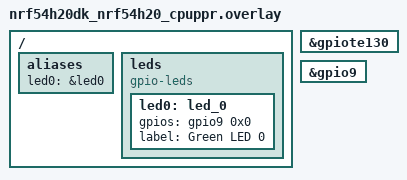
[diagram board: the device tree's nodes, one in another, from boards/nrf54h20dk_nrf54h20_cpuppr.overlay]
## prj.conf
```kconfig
CONFIG_ZTEST=y
CONFIG_GPIO=y
CONFIG_GPIO_GET_DIRECTION=y
```

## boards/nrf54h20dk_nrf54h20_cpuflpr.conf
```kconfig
# SPDX-License-Identifier: Apache-2.0

# FLPR does not support GPIO interrupts. Disabling interrupt support removes
# the driver's dependency on the (disabled-by-default) GPIOTE130 peripheral,
CONFIG_GPIO_NRFX_INTERRUPT=n
```

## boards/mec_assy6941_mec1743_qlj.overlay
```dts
/*
 * Copyright 2025 Microchip Technology Inc.
 *
 * SPDX-License-Identifier: Apache-2.0
 */

#include <dt-bindings/gpio/gpio.h>

/ {
	aliases {
		led0 = &led_G3;
	};

	gpio-led {
		compatible = "gpio-leds";

		led_G3: led_G3 {
			gpios = <&gpio_140_176 15 GPIO_ACTIVE_HIGH>;
		};
	};
};
```

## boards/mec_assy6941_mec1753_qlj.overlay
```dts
/*
 * Copyright 2025 Microchip Technology Inc.
 *
 * SPDX-License-Identifier: Apache-2.0
 */

#include <dt-bindings/gpio/gpio.h>

/ {
	aliases {
		led0 = &led_G3;
	};

	gpio-led {
		compatible = "gpio-leds";
		led_G3: led_G3 {
			gpios = <&gpio_140_176 15 GPIO_ACTIVE_HIGH>;
		};
	};
};
```

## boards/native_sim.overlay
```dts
&gpio0 {
	ngpios = <2>;
};
```

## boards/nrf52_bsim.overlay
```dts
/*
 * Copyright (c) 2023 Nordic Semiconductor ASA
 *
 * SPDX-License-Identifier: Apache-2.0
 */

/ {
	aliases {
		led0 = &led0;
	};

	leds {
		compatible = "gpio-leds";

		led0: led_0 {
			gpios = <&gpio0 0 GPIO_ACTIVE_HIGH>;
		};
	};
};
```

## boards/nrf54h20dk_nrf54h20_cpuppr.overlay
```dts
/* SPDX-License-Identifier: Apache-2.0 */

/ {
	aliases {
		led0 = &led0;
	};

	leds {
		compatible = "gpio-leds";
		led0: led_0 {
			gpios = < &gpio9 0x0 0x0 >;
			label = "Green LED 0";
		};
	};
};

&gpiote130 {
	status = "okay";
};

&gpio9 {
	status = "okay";
};
```

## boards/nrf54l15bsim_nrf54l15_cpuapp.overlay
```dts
/*
 * Copyright (c) 2024 Nordic Semiconductor ASA
 *
 * SPDX-License-Identifier: Apache-2.0
 */

#include "nrf52_bsim.overlay"
```

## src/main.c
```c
/*
 * Copyright (c) 2022 Meta
 *
 * SPDX-License-Identifier: Apache-2.0
 */

#include <zephyr/kernel.h>
#include <zephyr/drivers/gpio.h>
#include <zephyr/ztest.h>

#define TEST_NODE            DT_GPIO_CTLR(DT_ALIAS(led0), gpios)
#define TEST_PIN             DT_GPIO_PIN(DT_ALIAS(led0), gpios)
#define TEST_PIN_DTS_FLAGS   DT_GPIO_FLAGS(DT_ALIAS(led0), gpios)

struct gpio_get_direction_fixture {
	const struct device *port;
	gpio_pin_t pin;
	gpio_flags_t flags;
};

static void *gpio_get_direction_setup(void)
{
	static struct gpio_get_direction_fixture fixture;

	fixture.pin = TEST_PIN;
	fixture.port = DEVICE_DT_GET(TEST_NODE);

	return &fixture;
}

static void gpio_get_direction_before(void *arg)
{
	struct gpio_get_direction_fixture *fixture = (struct gpio_get_direction_fixture *)arg;

	zassert_true(device_is_ready(fixture->port), "GPIO device is not ready");
}

static void common(struct gpio_get_direction_fixture *fixture)
{
	int rv;

	rv = gpio_pin_configure(fixture->port, fixture->pin, fixture->flags);
	if (rv == -ENOTSUP) {
		/* some drivers / hw might not support e.g. input-output or disconnect */
		ztest_test_skip();
	}

	zassert_ok(rv, "gpio_pin_configure() failed: %d", rv);
}

ZTEST_F(gpio_get_direction, test_disconnect)
{
	int rv;

	fixture->flags = GPIO_DISCONNECTED;
	common(fixture);

	rv = gpio_pin_is_input(fixture->port, fixture->pin);
	if (rv == -ENOSYS) {
		/* gpio_pin_direction() is not supported in the driver */
		ztest_test_skip();
	}

	zassert_equal(false, rv, "gpio_pin_is_input() failed: %d", rv);

	rv = gpio_pin_is_output(fixture->port, fixture->pin);
	zassert_equal(false, rv, "gpio_pin_is_output() failed: %d", rv);
}

ZTEST_F(gpio_get_direction, test_input)
{
	int rv;
	fixture->flags = GPIO_INPUT;

	common(fixture);

	rv = gpio_pin_is_input(fixture->port, fixture->pin);
	if (rv == -ENOSYS) {
		/* gpio_pin_direction() is not supported in the driver */
		ztest_test_skip();
	}

	zassert_equal(true, rv, "gpio_pin_is_input() failed: %d", rv);

	rv = gpio_pin_is_output(fixture->port, fixture->pin);
	zassert_equal(false, rv, "gpio_pin_is_output() failed: %d", rv);
}

ZTEST_F(gpio_get_direction, test_output)
{
	int rv;
	fixture->flags = GPIO_OUTPUT | GPIO_OUTPUT_INIT_LOW;

	common(fixture);

	rv = gpio_pin_is_input(fixture->port, fixture->pin);
	if (rv == -ENOSYS) {
		/* gpio_pin_direction() is not supported in the driver */
		ztest_test_skip();
	}

	zassert_equal(false, rv, "gpio_pin_is_input() failed: %d", rv);

	rv = gpio_pin_is_output(fixture->port, fixture->pin);
	zassert_equal(true, rv, "gpio_pin_is_output() failed: %d", rv);
}

ZTEST_F(gpio_get_direction, test_input_output)
{
	int rv;
	fixture->flags = GPIO_INPUT | GPIO_OUTPUT | GPIO_OUTPUT_INIT_LOW;

	common(fixture);

	rv = gpio_pin_is_input(fixture->port, fixture->pin);
	if (rv == -ENOSYS) {
		/* some drivers / gpio hw do not support input-output mode */
		ztest_test_skip();
	}

	zassert_equal(true, rv, "gpio_pin_is_input() failed: %d", rv);

	rv = gpio_pin_is_output(fixture->port, fixture->pin);
	zassert_equal(true, rv, "gpio_pin_is_output() failed: %d", rv);
}

ZTEST_SUITE(gpio_get_direction, NULL, gpio_get_direction_setup, gpio_get_direction_before, NULL,
	    NULL);
```

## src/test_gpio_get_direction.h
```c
/*
 * Copyright (c) 2022 Meta
 *
 * SPDX-License-Identifier: Apache-2.0
 */

#ifndef TEST_GPIO_GET_DIRECTION_H_
#define TEST_GPIO_GET_DIRECTION_H_

#include <zephyr/zephyr.h>
#include <zephyr/drivers/gpio.h>
#include <ztest.h>

#if DT_NODE_HAS_PROP(DT_ALIAS(led0), gpios)
#define TEST_DEV             DT_GPIO_LABEL(DT_ALIAS(led0), gpios)
#define TEST_PIN             DT_GPIO_PIN(DT_ALIAS(led0), gpios)
#define TEST_PIN_DTS_FLAGS   DT_GPIO_FLAGS(DT_ALIAS(led0), gpios)
#else
#error Unsupported board
#endif

#endif /* TEST_GPIO_GET_DIRECTION_H_ */
```
